# HDSC_HC32F480 register map
Vendor: HDSC Co.Ltd; Series: ARMCM4; File version: 1.2
CPU: CM0 r0p0, little endian, no MPU, no FPU, 3 interrupt priority bits
Registers are 16-bit, read-write, reset 0x0 unless marked. A register's access mark holds for its fields unless they carry their own. Offsets are from the block's base; [hi:lo] are bit positions; {n}, {i} and the like mark numbered series; 'fields as' and 'values as' point back to an identical list.

## AOS
Base 0x40010800
0x00 INTSFTTRG 8-bit wo
  [0] STRG
{0x4+8i} ADC{i}_ITRGSELR0 (i=0..2)
  [8:0] TRGSEL
{0x8+8i} ADC{i}_ITRGSELR1 (i=0..2)
  [8:0] TRGSEL
0x1C TMR0_HTSSR
  [8:0] TRGSEL
0x20 TMR2_HTSSR
  [8:0] TRGSEL
{0x20+4i} PEVNTTRGSR{i} (i=1..4)
  [8:0] TRGSEL
{0x34+4i} TMR6_HTSSR{i} (i=0..3)
  [8:0] TRGSEL
{0x44+4i} DCU{i}_TRGSEL (i=0..3)
  [8:0] TRGSEL
{0x54+4i} DMA_TRGSEL{i} (i=0..5)
  [8:0] TRGSEL
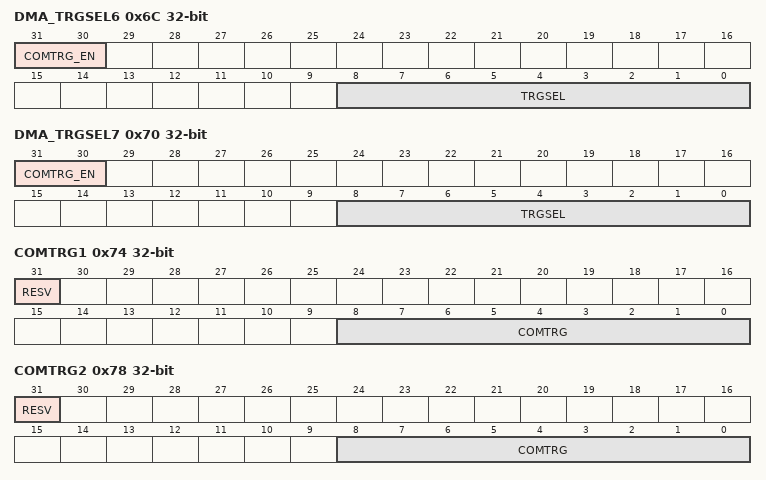
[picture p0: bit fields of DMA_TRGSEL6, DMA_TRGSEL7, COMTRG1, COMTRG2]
0x6C DMA_TRGSEL6 32-bit
  [31:30] COMTRG_EN, [8:0] TRGSEL
0x70 DMA_TRGSEL7 32-bit
  [31:30] COMTRG_EN, [8:0] TRGSEL
0x74 COMTRG1 32-bit
  [31] RESV, [8:0] COMTRG
0x78 COMTRG2 32-bit
  [31] RESV, [8:0] COMTRG
{0xE4+0x1C*i} PEVNTDIRR{i} (i=1..4)
{0xE8+0x1C*i} PEVNTIDR{i} ro (i=1..4)
{0xEC+0x1C*i} PEVNTODR{i} (i=1..4)
{0xF0+0x1C*i} PEVNTORR{i} (i=1..4)
{0xF4+0x1C*i} PEVNTOSR{i} (i=1..4)
{0xF8+0x1C*i} PEVNTRISR{i} (i=1..4)
{0xFC+0x1C*i} PEVNTFAL{i} (i=1..4)
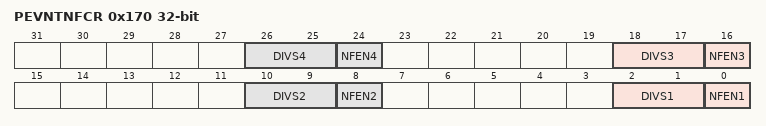
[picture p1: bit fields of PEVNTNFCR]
0x170 PEVNTNFCR 32-bit
  [8n-6:8n-7] DIVS{n} (n=1..4), [8n-8] NFEN{n} (n=1..4)

## CAN_0
Base 0x40016000
Same registers: CAN_1 0x40021400
{0x0+4i} RBUF_{i} 32-bit ro (i=0..3)
{0x50+4i} TBUF_{i} 32-bit (i=0..3)
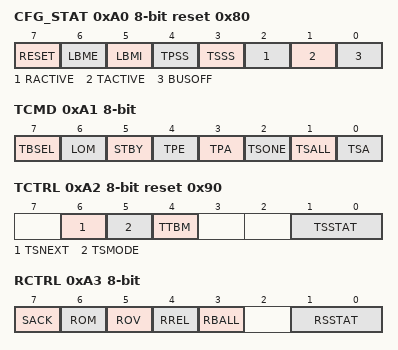
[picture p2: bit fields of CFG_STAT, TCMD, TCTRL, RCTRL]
0xA0 CFG_STAT 8-bit reset 0x80
  [7] RESET, [6] LBME, [5] LBMI, [4] TPSS, [3] TSSS, [2] RACTIVE ro, [1] TACTIVE ro, [0] BUSOFF
0xA1 TCMD 8-bit
  [7] TBSEL, [6] LOM, [5] STBY, [4] TPE, [3] TPA, [2] TSONE, [1] TSALL, [0] TSA
0xA2 TCTRL 8-bit ro reset 0x90
  [6] TSNEXT rw, [5] TSMODE rw, [4] TTBM rw, [1:0] TSSTAT
0xA3 RCTRL 8-bit ro
  [7] SACK rw, [6] ROM rw, [5] ROV, [4] RREL rw, [3] RBALL rw, [1:0] RSSTAT
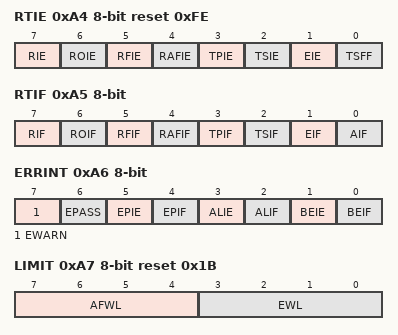
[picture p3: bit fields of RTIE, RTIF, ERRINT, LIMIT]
0xA4 RTIE 8-bit ro reset 0xFE
  [7] RIE rw, [6] ROIE rw, [5] RFIE rw, [4] RAFIE rw, [3] TPIE rw, [2] TSIE rw, [1] EIE rw, [0] TSFF
0xA5 RTIF 8-bit
  [7] RIF, [6] ROIF, [5] RFIF, [4] RAFIF, [3] TPIF, [2] TSIF, [1] EIF, [0] AIF
0xA6 ERRINT 8-bit
  [7] EWARN ro, [6] EPASS ro, [5] EPIE, [4] EPIF, [3] ALIE, [2] ALIF, [1] BEIE, [0] BEIF
0xA7 LIMIT 8-bit reset 0x1B
  [7:4] AFWL, [3:0] EWL
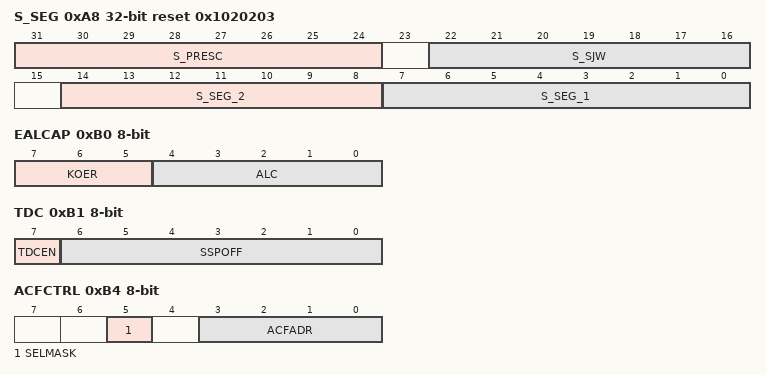
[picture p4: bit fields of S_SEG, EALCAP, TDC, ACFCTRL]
0xA8 S_SEG 32-bit reset 0x1020203
  [31:24] S_PRESC, [22:16] S_SJW, [14:8] S_SEG_2, [7:0] S_SEG_1
0xB0 EALCAP 8-bit ro
  [7:5] KOER, [4:0] ALC
0xB1 TDC 8-bit
  [7] TDCEN, [6:0] SSPOFF
0xB2 RECNT 8-bit
0xB3 TECNT 8-bit
0xB4 ACFCTRL 8-bit
  [5] SELMASK, [3:0] ACFADR
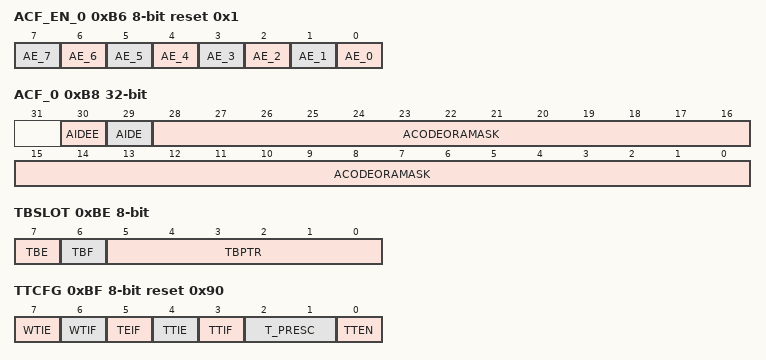
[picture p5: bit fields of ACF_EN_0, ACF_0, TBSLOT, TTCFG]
0xB6 ACF_EN_0 8-bit reset 0x1
  [n] AE_{n} (n=0..7)
0xB8 ACF_0 32-bit
  [30] AIDEE, [29] AIDE, [28:0] ACODEORAMASK
0xBC VER ro reset 0x516
0xBE TBSLOT 8-bit
  [7] TBE, [6] TBF, [5:0] TBPTR
0xBF TTCFG 8-bit reset 0x90
  [7] WTIE, [6] WTIF, [5] TEIF, [4] TTIE, [3] TTIF, [2:1] T_PRESC, [0] TTEN
0xC0 REF_MSG 32-bit
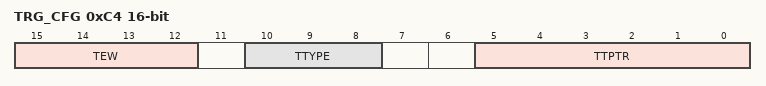
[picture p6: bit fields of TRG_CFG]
0xC4 TRG_CFG
  [15:12] TEW, [10:8] TTYPE, [5:0] TTPTR
0xC6 TT_TRIG
0xC8 TT_WTRIG reset 0xFFFF

## CMP
Base 0x4004A000
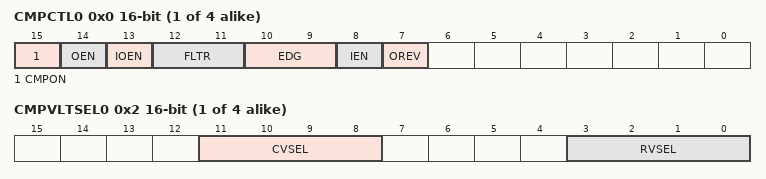
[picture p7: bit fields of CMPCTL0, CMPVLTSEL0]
{0x0+0x10*i} CMPCTL{i} (i=0..3)
  [15] CMPON, [14] OEN, [13] IOEN, [12:11] FLTR, [10:9] EDG, [8] IEN, [7] OREV
{0x2+0x10*i} CMPVLTSEL{i} (i=0..3)
  [11:8] CVSEL, [3:0] RVSEL
{0x4+0x10*i} CMPMON{i} 8-bit ro (i=0..3)
  [0] OMON

## CRC
Base 0x40008800
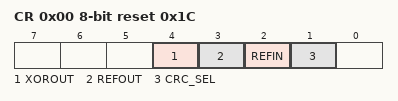
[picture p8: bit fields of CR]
0x00 CR 8-bit reset 0x1C
  [4] XOROUT, [3] REFOUT, [2] REFIN, [1] CRC_SEL
0x04 RESLT 32-bit reset 0x7800
0x0C FLG 8-bit ro reset 0x1
  [0] CRC_FLAG
{0x80+4i} DAT{i} 32-bit ro (i=0..31)

## DAC
Base 0x40041000
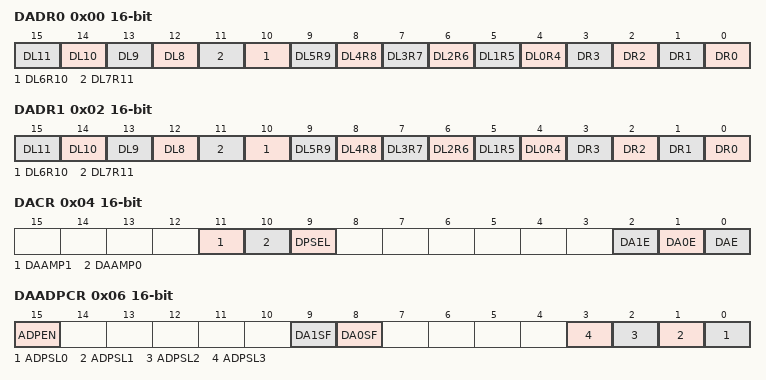
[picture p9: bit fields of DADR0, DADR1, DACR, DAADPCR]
0x00 DADR0
  [n+4] DL{n} (n=8..11), [n+4] DL{n}R{n+4} (n=0..7), [n] DR{n} (n=0..3)
0x02 DADR1
  fields as DADR0
0x04 DACR
  [11] DAAMP1, [10] DAAMP0, [9] DPSEL, [2] DA1E, [1] DA0E, [0] DAE
0x06 DAADPCR
  [15] ADPEN, [9] DA1SF ro, [8] DA0SF ro, [n] ADPSL{n} (n=0..3)
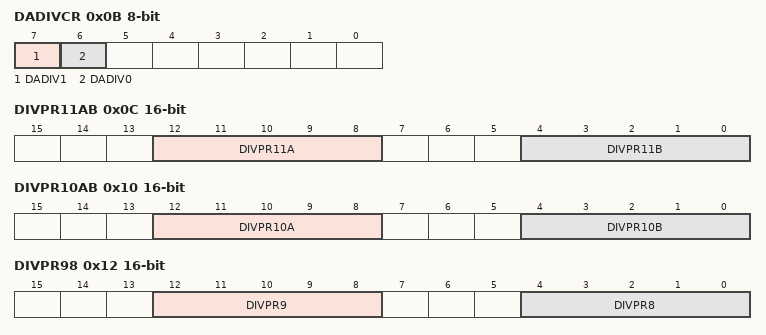
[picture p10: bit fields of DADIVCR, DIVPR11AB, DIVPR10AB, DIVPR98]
0x0B DADIVCR 8-bit
  [7] DADIV1, [6] DADIV0
0x0C DIVPR11AB
  [12:8] DIVPR11A, [4:0] DIVPR11B
0x0E DIVPR11C
  [12:8] DIVPR11C
0x10 DIVPR10AB
  [12:8] DIVPR10A, [4:0] DIVPR10B
0x12 DIVPR98
  [12:8] DIVPR9, [4:0] DIVPR8
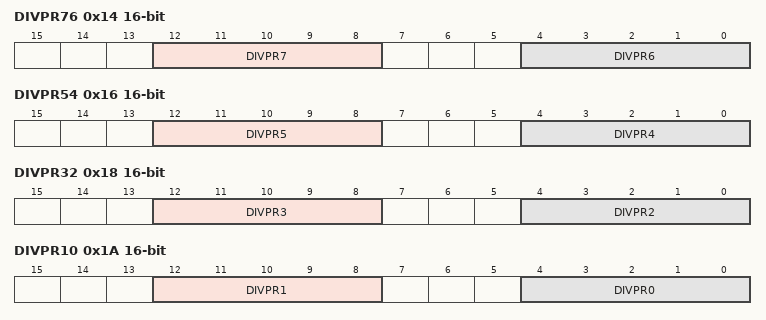
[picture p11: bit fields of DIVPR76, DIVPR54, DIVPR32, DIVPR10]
0x14 DIVPR76
  [12:8] DIVPR7, [4:0] DIVPR6
0x16 DIVPR54
  [12:8] DIVPR5, [4:0] DIVPR4
0x18 DIVPR32
  [12:8] DIVPR3, [4:0] DIVPR2
0x1A DIVPR10
  [12:8] DIVPR1, [4:0] DIVPR0
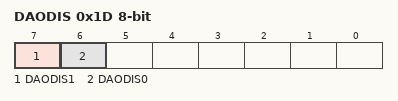
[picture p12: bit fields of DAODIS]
0x1D DAODIS 8-bit
  [7] DAODIS1, [6] DAODIS0
